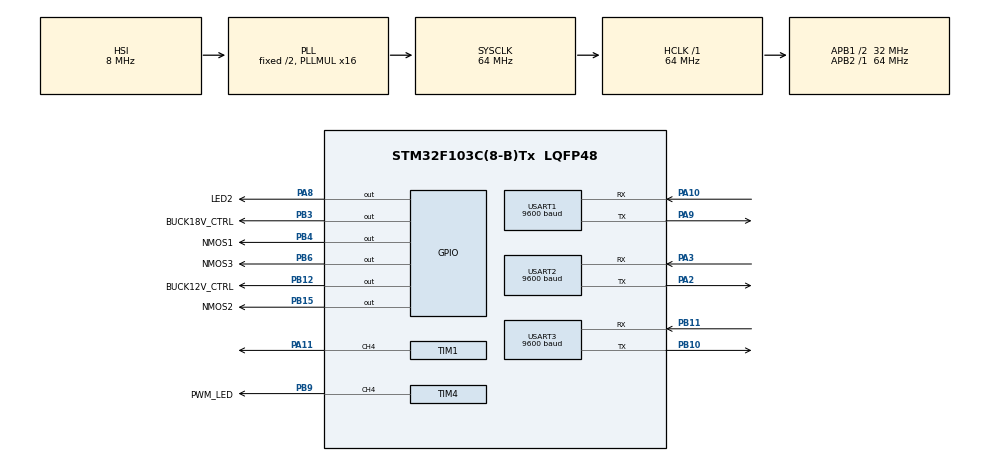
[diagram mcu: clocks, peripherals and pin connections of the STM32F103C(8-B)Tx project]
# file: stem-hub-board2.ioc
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FREERTOS.Tasks01=systemTask,24,128,StartSystemTask,Default,NULL,Dynamic,NULL,NULL;atTask,32,256,StartAtTask,Default,NULL,Dynamic,NULL,NULL;bridgeTask,24,256,StartBridgeTask,Default,NULL,Dynamic,NULL,NULL
FREERTOS.configTOTAL_HEAP_SIZE=6144
Mcu.Family=STM32F1
Mcu.Name=STM32F103C(8-B)Tx
Mcu.Package=LQFP48
NVIC.PriorityGroup=NVIC_PRIORITYGROUP_4
NVIC.TIM3_IRQn=true\:15\:0\:false\:false\:true\:false\:false\:true\:true
NVIC.TimeBase=TIM3_IRQn
NVIC.TimeBaseIP=TIM3
NVIC.USART1_IRQn=true\:5\:0\:false\:false\:true\:true\:false\:true\:true
NVIC.USART2_IRQn=true\:5\:0\:false\:false\:true\:true\:false\:true\:true
NVIC.USART3_IRQn=true\:5\:0\:false\:false\:true\:true\:false\:true\:true
PA10.Mode=Asynchronous
PA10.Signal=USART1_RX
PA11.Signal=S_TIM1_CH4
PA13.Mode=Serial_Wire
PA13.Signal=SYS_JTMS-SWDIO
PA14.Mode=Serial_Wire
PA14.Signal=SYS_JTCK-SWCLK
PA2.Mode=Asynchronous
PA2.Signal=USART2_TX
PA3.Mode=Asynchronous
PA3.Signal=USART2_RX
PA8.GPIO_Label=LED2
PA8.Signal=GPIO_Output
PA9.Mode=Asynchronous
PA9.Signal=USART1_TX
PB10.Mode=Asynchronous
PB10.Signal=USART3_TX
PB11.Mode=Asynchronous
PB11.Signal=USART3_RX
PB12.GPIO_Label=BUCK12V_CTRL
PB12.PinState=GPIO_PIN_SET
PB12.Signal=GPIO_Output
PB15.GPIO_Label=NMOS2
PB15.PinState=GPIO_PIN_RESET
PB15.Signal=GPIO_Output
PB3.GPIO_Label=BUCK18V_CTRL
PB3.PinState=GPIO_PIN_SET
PB3.Signal=GPIO_Output
PB4.GPIO_Label=NMOS1
PB4.PinState=GPIO_PIN_RESET
PB4.Signal=GPIO_Output
PB6.GPIO_Label=NMOS3
PB6.PinState=GPIO_PIN_RESET
PB6.Signal=GPIO_Output
PB9.GPIO_Label=PWM_LED
PB9.Signal=S_TIM4_CH4
ProjectManager.HeapSize=0x200
ProjectManager.StackSize=0x400
ProjectManager.TargetToolchain=CMake
RCC.AHBFreq_Value=64000000
RCC.APB1CLKDivider=RCC_HCLK_DIV2
RCC.APB1Freq_Value=32000000
RCC.APB1TimFreq_Value=64000000
RCC.APB2Freq_Value=64000000
RCC.APB2TimFreq_Value=64000000
RCC.HCLKFreq_Value=64000000
RCC.PLLMUL=RCC_PLL_MUL16
RCC.SYSCLKFreq_VALUE=64000000
RCC.SYSCLKSource=RCC_SYSCLKSOURCE_PLLCLK
RCC.USBFreq_Value=64000000
SH.S_TIM1_CH4.0=TIM1_CH4,PWM Generation4 CH4
SH.S_TIM4_CH4.0=TIM4_CH4,PWM Generation4 CH4
TIM1.Channel-PWM\ Generation4\ CH4=TIM_CHANNEL_4
TIM4.Channel-PWM\ Generation1\ No\ Output=TIM_CHANNEL_1
TIM4.Channel-PWM\ Generation4\ CH4=TIM_CHANNEL_4
TIM4.Period=2559
TIM4.Prescaler=0
USART1.BaudRate=9600
USART1.VirtualMode=VM_ASYNC
USART2.BaudRate=9600
USART2.VirtualMode=VM_ASYNC
USART3.BaudRate=9600
USART3.VirtualMode=VM_ASYNC
VP_FREERTOS_VS_CMSIS_V2.Mode=CMSIS_V2
VP_SYS_VS_tim3.Mode=TIM3
VP_TIM4_VS_ClockSourceINT.Mode=Internal
VP_TIM4_VS_no_output1.Mode=PWM Generation1 No Output
board=custom

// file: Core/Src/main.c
/* USER CODE BEGIN Header */
/**
  ******************************************************************************
  * @file           : main.c
  * @brief          : Main program body
  ******************************************************************************
  * @attention
  *
  * Copyright (c) 2026 STMicroelectronics.
  * All rights reserved.
  *
  * This software is licensed under terms that can be found in the LICENSE file
  * in the root directory of this software component.
  * If no LICENSE file comes with this software, it is provided AS-IS.
  *
  ******************************************************************************
  */
/* USER CODE END Header */
#include "main.h"
#include "cmsis_os.h"
#include "tim.h"
#include "usart.h"
#include "gpio.h"

void SystemClock_Config(void);
void MX_FREERTOS_Init(void);

int main(void)
{

  /* MCU Configuration--------------------------------------------------------*/

  /* Reset of all peripherals, Initializes the Flash interface and the Systick. */
  HAL_Init();

  /* Configure the system clock */
  SystemClock_Config();

  /* Initialize all configured peripherals */
  MX_GPIO_Init();
  MX_TIM1_Init();
  MX_TIM4_Init();
  MX_USART1_UART_Init();
  MX_USART2_UART_Init();
  MX_USART3_UART_Init();

  /* Init scheduler */
  osKernelInitialize();  /* Call init function for freertos objects (in cmsis_os2.c) */
  MX_FREERTOS_Init();

  /* Start scheduler */
  osKernelStart();

  /* We should never get here as control is now taken by the scheduler */

  /* Infinite loop */
  while (1)
  {

  }
}

void SystemClock_Config(void)
{
  RCC_OscInitTypeDef RCC_OscInitStruct = {0};
  RCC_ClkInitTypeDef RCC_ClkInitStruct = {0};

  /** Initializes the RCC Oscillators according to the specified parameters
  * in the RCC_OscInitTypeDef structure.
  */
  RCC_OscInitStruct.OscillatorType = RCC_OSCILLATORTYPE_HSI;
  RCC_OscInitStruct.HSIState = RCC_HSI_ON;
  RCC_OscInitStruct.HSICalibrationValue = RCC_HSICALIBRATION_DEFAULT;
  RCC_OscInitStruct.PLL.PLLState = RCC_PLL_ON;
  RCC_OscInitStruct.PLL.PLLSource = RCC_PLLSOURCE_HSI_DIV2;
  RCC_OscInitStruct.PLL.PLLMUL = RCC_PLL_MUL16;
  if (HAL_RCC_OscConfig(&RCC_OscInitStruct) != HAL_OK)
  {
    Error_Handler();
  }

  /** Initializes the CPU, AHB and APB buses clocks
  */
  RCC_ClkInitStruct.ClockType = RCC_CLOCKTYPE_HCLK|RCC_CLOCKTYPE_SYSCLK
                              |RCC_CLOCKTYPE_PCLK1|RCC_CLOCKTYPE_PCLK2;
  RCC_ClkInitStruct.SYSCLKSource = RCC_SYSCLKSOURCE_PLLCLK;
  RCC_ClkInitStruct.AHBCLKDivider = RCC_SYSCLK_DIV1;
  RCC_ClkInitStruct.APB1CLKDivider = RCC_HCLK_DIV2;
  RCC_ClkInitStruct.APB2CLKDivider = RCC_HCLK_DIV1;

  if (HAL_RCC_ClockConfig(&RCC_ClkInitStruct, FLASH_LATENCY_2) != HAL_OK)
  {
    Error_Handler();
  }
}

void HAL_TIM_PeriodElapsedCallback(TIM_HandleTypeDef *htim)
{
  if (htim->Instance == TIM3)
  {
    HAL_IncTick();
  }
}

void Error_Handler(void)
{
  __disable_irq();
  while (1)
  {
  }
}

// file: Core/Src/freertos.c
/* USER CODE BEGIN Header */
/**
  ******************************************************************************
  * File Name          : freertos.c
  * Description        : Code for freertos applications
  ******************************************************************************
  * @attention
  *
  * Copyright (c) 2026 STMicroelectronics.
  * All rights reserved.
  *
  * This software is licensed under terms that can be found in the LICENSE file
  * in the root directory of this software component.
  * If no LICENSE file comes with this software, it is provided AS-IS.
  *
  ******************************************************************************
  */
/* USER CODE END Header */

#include "FreeRTOS.h"
#include "task.h"
#include "main.h"
#include "cmsis_os.h"

/* USER CODE BEGIN Includes */
#include "app_runtime.h"
#include "app_output.h"
#include "app_tasks.h"

/* USER CODE END Includes */

/* Definitions for systemTask */
osThreadId_t systemTaskHandle;
const osThreadAttr_t systemTask_attributes = {
  .name = "systemTask",
  .stack_size = 128 * 4,
  .priority = (osPriority_t) osPriorityNormal,
};
/* Definitions for atTask */
osThreadId_t atTaskHandle;
const osThreadAttr_t atTask_attributes = {
  .name = "atTask",
  .stack_size = 256 * 4,
  .priority = (osPriority_t) osPriorityAboveNormal,
};
/* Definitions for bridgeTask */
osThreadId_t bridgeTaskHandle;
const osThreadAttr_t bridgeTask_attributes = {
  .name = "bridgeTask",
  .stack_size = 256 * 4,
  .priority = (osPriority_t) osPriorityNormal,
};

void StartSystemTask(void *argument);
void StartAtTask(void *argument);
void StartBridgeTask(void *argument);

void MX_FREERTOS_Init(void); /* (MISRA C 2004 rule 8.1) */

void MX_FREERTOS_Init(void) {
  /* USER CODE BEGIN Init */
  App_OutputInit();
  App_RuntimeCreateObjects();

  /* USER CODE END Init */

  /* Create the thread(s) */
  /* creation of systemTask */
  systemTaskHandle = osThreadNew(StartSystemTask, NULL, &systemTask_attributes);

  /* creation of atTask */
  atTaskHandle = osThreadNew(StartAtTask, NULL, &atTask_attributes);

  /* creation of bridgeTask */
  bridgeTaskHandle = osThreadNew(StartBridgeTask, NULL, &bridgeTask_attributes);

}

void StartSystemTask(void *argument)
{
  /* USER CODE BEGIN StartSystemTask */
  App_SystemTask(argument);
  /* USER CODE END StartSystemTask */
}

void StartAtTask(void *argument)
{
  /* USER CODE BEGIN StartAtTask */
  App_AtTask(argument);
  /* USER CODE END StartAtTask */
}

void StartBridgeTask(void *argument)
{
  /* USER CODE BEGIN StartBridgeTask */
  App_BridgeTask(argument);
  /* USER CODE END StartBridgeTask */
}

/* USER CODE BEGIN Application */

void vApplicationStackOverflowHook(TaskHandle_t task_handle, char *task_name)
{
  (void)task_handle;
  (void)task_name;
  Error_Handler();
}

void vApplicationMallocFailedHook(void)
{
  Error_Handler();
}

/* USER CODE END Application */
